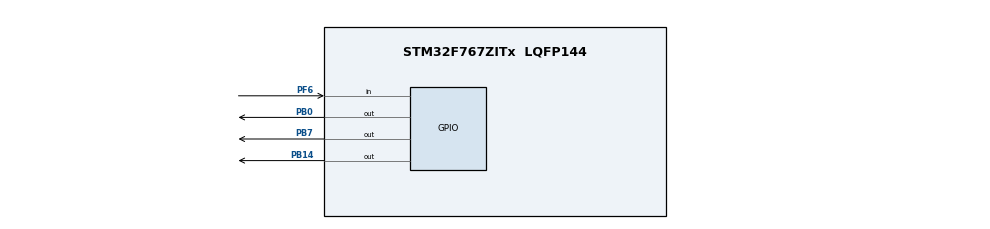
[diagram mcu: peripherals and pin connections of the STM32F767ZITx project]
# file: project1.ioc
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CORTEX_M7.default_mode_Activation=1
Mcu.Family=STM32F7
Mcu.Name=STM32F767ZITx
Mcu.Package=LQFP144
NVIC.PriorityGroup=NVIC_PRIORITYGROUP_4
PB0.Signal=GPIO_Output
PB14.Signal=GPIO_Output
PB7.Signal=GPIO_Output
PF6.Signal=GPIO_Input
ProjectManager.HeapSize=0x200
ProjectManager.StackSize=0x400
ProjectManager.TargetToolchain=Makefile
RCC.HSE_VALUE=25000000
RCC.HSI_VALUE=16000000
RCC.LSE_VALUE=32768
RCC.USBFreq_Value=96000000
RCC.VCOOutputFreq_Value=192000000
board=custom

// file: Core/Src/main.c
/* USER CODE BEGIN Header */
/**
  ******************************************************************************
  * @file           : main.c
  * @brief          : Main program body
  ******************************************************************************
  * @attention
  *
  * Copyright (c) 2024 STMicroelectronics.
  * All rights reserved.
  *
  * This software is licensed under terms that can be found in the LICENSE file
  * in the root directory of this software component.
  * If no LICENSE file comes with this software, it is provided AS-IS.
  *
  ******************************************************************************
  */
/* USER CODE END Header */
#include "main.h"
#include "gpio.h"

void SystemClock_Config(void);
static void MPU_Config(void);

int main(void)
{

  /* MPU Configuration--------------------------------------------------------*/
  MPU_Config();

  /* MCU Configuration--------------------------------------------------------*/

  /* Reset of all peripherals, Initializes the Flash interface and the Systick. */
  HAL_Init();

  /* Configure the system clock */
  SystemClock_Config();

  /* Initialize all configured peripherals */
  MX_GPIO_Init();

  /* Infinite loop */
  while (1)
  {

    /* USER CODE BEGIN 3 */
    HAL_GPIO_WritePin(GPIOB, GPIO_PIN_0, GPIO_PIN_RESET); //LD1 connected to PB0 doesn't work
    HAL_GPIO_WritePin(GPIOB, GPIO_PIN_7, GPIO_PIN_SET);
    HAL_GPIO_WritePin(GPIOB, GPIO_PIN_14, GPIO_PIN_SET);
  }
  /* USER CODE END 3 */
}

void SystemClock_Config(void)
{
  RCC_OscInitTypeDef RCC_OscInitStruct = {0};
  RCC_ClkInitTypeDef RCC_ClkInitStruct = {0};

  /** Configure the main internal regulator output voltage
  */
  __HAL_RCC_PWR_CLK_ENABLE();
  __HAL_PWR_VOLTAGESCALING_CONFIG(PWR_REGULATOR_VOLTAGE_SCALE3);

  /** Initializes the RCC Oscillators according to the specified parameters
  * in the RCC_OscInitTypeDef structure.
  */
  RCC_OscInitStruct.OscillatorType = RCC_OSCILLATORTYPE_HSI;
  RCC_OscInitStruct.HSIState = RCC_HSI_ON;
  RCC_OscInitStruct.HSICalibrationValue = RCC_HSICALIBRATION_DEFAULT;
  RCC_OscInitStruct.PLL.PLLState = RCC_PLL_NONE;
  if (HAL_RCC_OscConfig(&RCC_OscInitStruct) != HAL_OK)
  {
    Error_Handler();
  }

  /** Initializes the CPU, AHB and APB buses clocks
  */
  RCC_ClkInitStruct.ClockType = RCC_CLOCKTYPE_HCLK|RCC_CLOCKTYPE_SYSCLK
                              |RCC_CLOCKTYPE_PCLK1|RCC_CLOCKTYPE_PCLK2;
  RCC_ClkInitStruct.SYSCLKSource = RCC_SYSCLKSOURCE_HSI;
  RCC_ClkInitStruct.AHBCLKDivider = RCC_SYSCLK_DIV1;
  RCC_ClkInitStruct.APB1CLKDivider = RCC_HCLK_DIV1;
  RCC_ClkInitStruct.APB2CLKDivider = RCC_HCLK_DIV1;

  if (HAL_RCC_ClockConfig(&RCC_ClkInitStruct, FLASH_LATENCY_0) != HAL_OK)
  {
    Error_Handler();
  }
}

 /* MPU Configuration */

void MPU_Config(void)
{
  MPU_Region_InitTypeDef MPU_InitStruct = {0};

  /* Disables the MPU */
  HAL_MPU_Disable();

  /** Initializes and configures the Region and the memory to be protected
  */
  MPU_InitStruct.Enable = MPU_REGION_ENABLE;
  MPU_InitStruct.Number = MPU_REGION_NUMBER0;
  MPU_InitStruct.BaseAddress = 0x0;
  MPU_InitStruct.Size = MPU_REGION_SIZE_4GB;
  MPU_InitStruct.SubRegionDisable = 0x87;
  MPU_InitStruct.TypeExtField = MPU_TEX_LEVEL0;
  MPU_InitStruct.AccessPermission = MPU_REGION_NO_ACCESS;
  MPU_InitStruct.DisableExec = MPU_INSTRUCTION_ACCESS_DISABLE;
  MPU_InitStruct.IsShareable = MPU_ACCESS_SHAREABLE;
  MPU_InitStruct.IsCacheable = MPU_ACCESS_NOT_CACHEABLE;
  MPU_InitStruct.IsBufferable = MPU_ACCESS_NOT_BUFFERABLE;

  HAL_MPU_ConfigRegion(&MPU_InitStruct);
  /* Enables the MPU */
  HAL_MPU_Enable(MPU_PRIVILEGED_DEFAULT);

}

void Error_Handler(void)
{
  __disable_irq();
  while (1)
  {
  }
}
